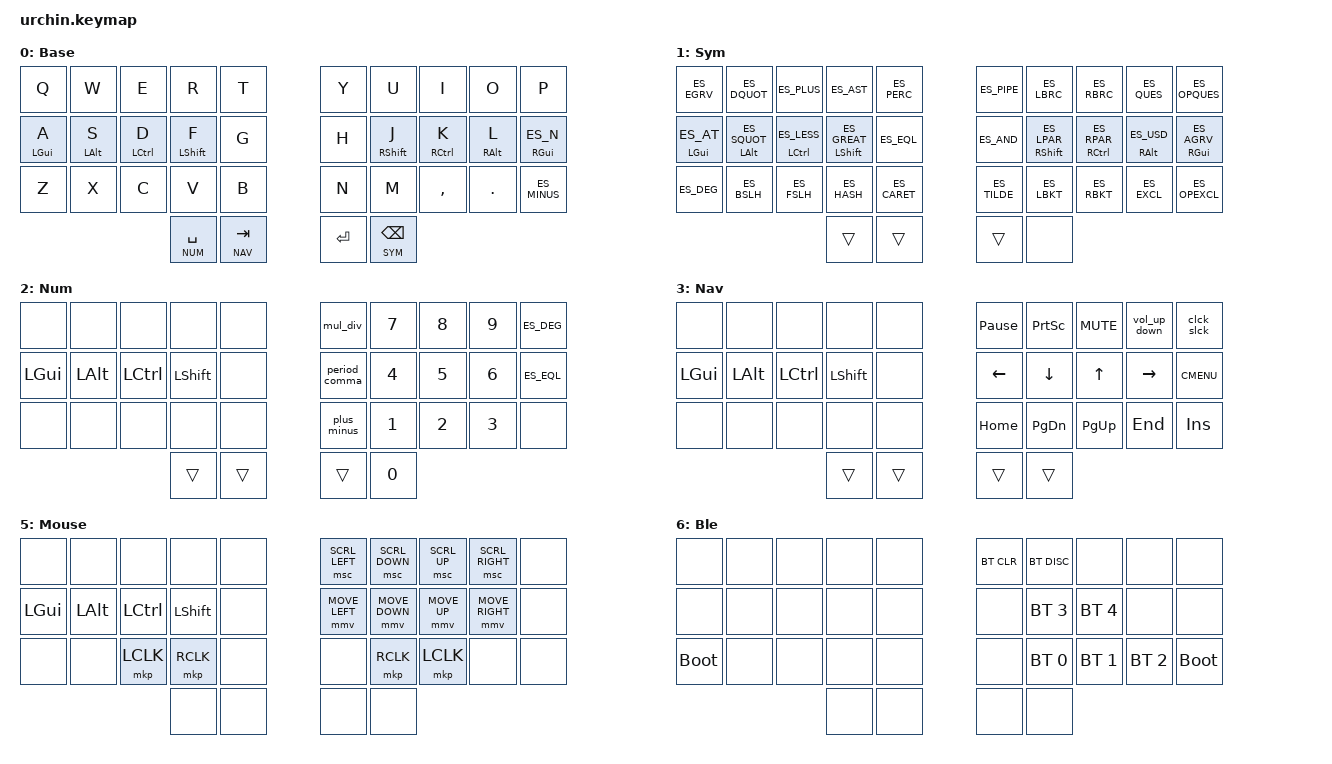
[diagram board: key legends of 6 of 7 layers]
/*
 * Copyright (c) 2020 duckyb
 *
 * SPDX-License-Identifier: MIT`
 */

#include <behaviors.dtsi>
#include <dt-bindings/zmk/keys.h>
#include <dt-bindings/zmk/bt.h>
#include <dt-bindings/zmk/outputs.h>

#define ZMK_POINTING_DEFAULT_MOVE_VAL 1500  // default: 600
#define ZMK_POINTING_DEFAULT_SCRL_VAL 20    // default: 10
#include <dt-bindings/zmk/pointing.h>

#include "keymap_spanish.h"

// Layer definitions
#define BASE 0
#define SYM 1
#define NUM 2
#define NAV 3
#define FUNC 4
#define MOUSE 5
#define BLE 6
// -----------------

#define xxx &none
#define ___ &trans


// tapping term definition
#define TAP_TERM_MS 300
#define QUICK_TAP_MS 300

// 34 keys physical layout
#define LEFT_KEYS 0 1 2 3 4 10 11 12 13 14 20 21 22 23 24 // left-hand keys
#define RIGHT_KEYS 5 6 7 8 9 15 16 17 18 19 25 26 27 28 29 // right-hand keys
#define THUMBS 30 31 32 33 // thumb keys


&sk {
	// don't release mods on other mods presses
	ignore-modifiers;
};

// layer tap config
&lt {
    flavor = "hold-preferred";
    tapping-term-ms = <TAP_TERM_MS>;
    quick-tap-ms = <QUICK_TAP_MS>;      // double-tap + hold repeats tap-key
};


/ {
	behaviors {
		// Enables holding the first mod-tap key
		// by performing a tap-release-hold sequence.
		// To use it: "&qt KEYCODE1 KEYCODE2"
		qt: quick_tap {
			compatible = "zmk,behavior-hold-tap";
			//label = "QUICK_TAP";
			#binding-cells = <2>;
			flavor = "hold-preferred";
			tapping-term-ms = <200>;
			quick-tap-ms = <200>;
			bindings = <&kp>, <&kp>;
		};

		// HOME ROW MODS
		hml: left_hand_positional_hold_tap {
			compatible = "zmk,behavior-hold-tap";
			#binding-cells = <2>;
			flavor = "balanced";
			tapping-term-ms = <TAP_TERM_MS>;
			quick-tap-ms = <QUICK_TAP_MS>;       // double-tap + hold repeats tap-key
			require-prior-idle-ms = <150>;       // do not activate HOLD during typing flow
			bindings = <&kp>, <&kp>;
			hold-trigger-key-positions = <RIGHT_KEYS THUMBS>;
			hold-trigger-on-release;
		};

		hmr: right_hand_positional_hold_tap {
			compatible = "zmk,behavior-hold-tap";
			#binding-cells = <2>;
			flavor = "balanced";
			tapping-term-ms = <TAP_TERM_MS>;
			quick-tap-ms = <QUICK_TAP_MS>;       // double-tap + hold repeats tap-key
			require-prior-idle-ms = <150>;       // do not activate HOLD during typing flow
			bindings = <&kp>, <&kp>;
			hold-trigger-key-positions = <LEFT_KEYS THUMBS>;
			hold-trigger-on-release;
		};

		// TAP DANCES
		plus_minus: plus_minus {
			compatible = "zmk,behavior-mod-morph";
			#binding-cells = <0>;
			bindings = <&kp ES_PLUS>, <&kp KP_MINUS>;
			mods = <(MOD_LSFT)>;
		};

		mul_div: mul_div {
			compatible = "zmk,behavior-mod-morph";
			#binding-cells = <0>;
			bindings = <&kp ES_AST>, <&kp ES_FSLH>;
			mods = <(MOD_LSFT)>;
		};

		period_comma: period_comma {
			compatible = "zmk,behavior-mod-morph";
			#binding-cells = <0>;
			bindings = <&kp PERIOD>, <&kp COMMA>;
			mods = <(MOD_LSFT)>;
		};

		clck_slck: clck_slck {
			compatible = "zmk,behavior-mod-morph";
			#binding-cells = <0>;
			bindings = <&kp CAPS>, <&kp SLCK>;
			mods = <(MOD_LSFT)>;
		};

		vol_up_down: vol_up_down {
			compatible = "zmk,behavior-mod-morph";
			#binding-cells = <0>;
			bindings = <&kp C_VOL_UP>, <&kp C_VOL_DN>;
			mods = <(MOD_LSFT)>;
		};
	};

	macros {
		// sometimes my device thinks a modifier is being held down
		// pressing all modifiers fixes it.
		unstick: unstick {
			//label = "ZM_unstick";
			compatible = "zmk,behavior-macro";
			#binding-cells = <0>;
			bindings = <&kp LSHIFT &kp RSHIFT &kp LCTRL &kp RCTRL &kp LALT &kp RALT &kp LGUI &kp RGUI>;
		};
	};

	combos {
		compatible = "zmk,combos";
		// both left thumb keys
		combo_function_keys {
			timeout-ms = <200>;
			key-positions = <30 31>;
			bindings = <&mo FUNC>;
		};

		combo_ble {
			timeout-ms = <200>;
			key-positions = <31 32>;
			bindings = <&mo BLE>;
		};

		combo_mouse {
			timeout-ms = <200>;
			key-positions = <31 33>;
			bindings = <&to MOUSE>;
		};

		combo_back_to_base {
			timeout-ms = <200>;
			key-positions = <23 24>;
			bindings = <&to BASE>;
			layers = <MOUSE>;
		};
		// left index & middle fingers (home-row)
		// hold control & space for Adobe workflow
		//combo_ctrl_space {
		//	timeout-ms = <200>;
		//	key-positions = <12 13>;
		//	bindings = <&kp LC(SPACE)>;
		//	layers = <BASE>;
		//};

    combo_esc {
        timeout-ms = <30>;
        key-positions = <22 23>; // keys that trigger it
        bindings = <&kp ESC>;
    };

    combo_supr {
        timeout-ms = <30>;
        key-positions = <26 27>; // keys that trigger it
        bindings = <&kp DEL>;
    };

	};

	keymap {
		compatible = "zmk,keymap";
		// Base alpha layer
		default_layer {
			label = "Base";
			bindings = <
				//╭──────────────┬──────────────┬──────────────┬──────────────┬──────────────╮   ╭──────────────┬──────────────┬──────────────┬──────────────┬──────────────╮
						&kp Q          &kp W          &kp E          &kp R          &kp T               &kp Y         &kp U          &kp I          &kp O          &kp P
				//├──────────────┼──────────────┼──────────────┼──────────────┼──────────────┤   ├──────────────┼──────────────┼──────────────┼──────────────┼──────────────┤
						&hml LGUI A    &hml LALT S    &hml LCTRL  D  &hml LSHFT F   &kp G               &kp H         &hmr RSHFT J  &hmr RCTRL K   &hmr RALT L    &hmr RGUI ES_N
				//├──────────────┼──────────────┼──────────────┼──────────────┼──────────────┤   ├──────────────┼──────────────┼──────────────┼──────────────┼──────────────┤
						&kp Z          &kp X          &kp C          &kp V          &kp B               &kp N         &kp M          &kp COMMA      &kp PERIOD     &kp ES_MINUS
				//╰──────────────┴──────────────┼──────────────┼──────────────┼──────────────┤   ├──────────────┼──────────────┼──────────────┼──────────────┴──────────────╯
																												 &lt NUM SPACE  &lt NAV TAB  				&kp RET 		  &lt SYM BSPC
             //                              					 ╰──────────────┴──────────────╯   ╰──────────────┴──────────────╯	
			>;
		};

		// High frequency symbols
		sym_layer {
			label = "Sym";
			bindings = <
				//╭──────────────┬──────────────┬──────────────┬──────────────┬──────────────╮     ╭──────────────┬──────────────┬──────────────┬──────────────┬──────────────╮
					  &kp ES_EGRV    &kp ES_DQUOT   &kp ES_PLUS    &kp ES_AST      &kp ES_PERC          &kp ES_PIPE   &kp ES_LBRC    &kp ES_RBRC    &kp ES_QUES    &kp ES_OPQUES
				//├──────────────┼──────────────┼──────────────┼──────────────┼──────────────┤     ├──────────────┼──────────────┼──────────────┼──────────────┼──────────────┤
			&hml LGUI ES_AT &hml LALT ES_SQUOT &hml LCTRL ES_LESS &hml LSHFT ES_GREAT &kp ES_EQL &kp ES_AND &hmr RSHFT ES_LPAR &hmr RCTRL ES_RPAR &hmr RALT ES_USD &hmr RGUI ES_AGRV
				//├──────────────┼──────────────┼──────────────┼──────────────┼──────────────┤     ├──────────────┼──────────────┼──────────────┼──────────────┼──────────────┤
					  &kp ES_DEG     &kp ES_BSLH    &kp ES_FSLH    &kp ES_HASH     &kp ES_CARET        &kp ES_TILDE  &kp ES_LBKT    &kp ES_RBKT    &kp ES_EXCL    &kp ES_OPEXCL
				//╰──────────────┴──────────────┼──────────────┼──────────────┼──────────────┤     ├──────────────┼──────────────┼──────────────┼──────────────┴──────────────╯
																													  ___            ___                  ___            xxx          
             //                                        ╰──────────────┴──────────────╯     ╰──────────────┴──────────────╯
			>;
		};

		// Number and math layer
		num_layer {
			label = "Num";
			bindings = <
				//╭──────────────┬──────────────┬──────────────┬──────────────┬──────────────╮     ╭──────────────┬──────────────┬──────────────┬──────────────┬──────────────╮
					  xxx            xxx            xxx            xxx            xxx                  &mul_div       &kp N7         &kp N8         &kp N9         &kp ES_DEG
				//├──────────────┼──────────────┼──────────────┼──────────────┼──────────────┤     ├──────────────┼──────────────┼──────────────┼──────────────┼──────────────┤
						&kp LGUI       &kp LALT       &kp LCTRL      &kp LSHFT      xxx                  &period_comma  &kp N4         &kp N5         &kp N6         &kp ES_EQL
				//├──────────────┼──────────────┼──────────────┼──────────────┼──────────────┤     ├──────────────┼──────────────┼──────────────┼──────────────┼──────────────┤
					  xxx            xxx            xxx            xxx            xxx                  &plus_minus    &kp N1         &kp N2         &kp N3         xxx
				//╰──────────────┴──────────────┼──────────────┼──────────────┼──────────────┤     ├──────────────┼──────────────┼──────────────┼──────────────┴──────────────╯
																													  ___            ___                  ___         &kp N0          
             //                                        ╰──────────────┴──────────────╯     ╰──────────────┴──────────────╯
			>;
		};

		// Navigation
		nav_layer {
			label = "Nav";
			bindings = <
				//╭──────────────┬──────────────┬──────────────┬──────────────┬──────────────╮     ╭──────────────┬──────────────┬──────────────┬──────────────┬──────────────╮
					  xxx            xxx            xxx            xxx            xxx                &kp PAUSE_BREAK  &kp PSCRN  		 &kp C_MUTE     &vol_up_down   &clck_slck
				//├──────────────┼──────────────┼──────────────┼──────────────┼──────────────┤     ├──────────────┼──────────────┼──────────────┼──────────────┼──────────────┤
						&kp LGUI       &kp LALT       &kp LCTRL      &kp LSHFT      xxx                  &kp LEFT       &kp DOWN       &kp UP         &kp RIGHT      &kp K_CMENU
				//├──────────────┼──────────────┼──────────────┼──────────────┼──────────────┤     ├──────────────┼──────────────┼──────────────┼──────────────┼──────────────┤
					  xxx            xxx            xxx            xxx            xxx                  &kp HOME       &kp PG_DN      &kp PG_UP      &kp END        &kp INS
				//╰──────────────┴──────────────┼──────────────┼──────────────┼──────────────┤     ├──────────────┼──────────────┼──────────────┼──────────────┴──────────────╯
																													  ___            ___                  ___            ___
             //                                        ╰──────────────┴──────────────╯     ╰──────────────┴──────────────╯
			>;
		};

		//Function
		func_layer {
			label = "Func";
			bindings = <
				//╭──────────────┬──────────────┬──────────────┬──────────────┬──────────────╮     ╭──────────────┬──────────────┬──────────────┬──────────────┬──────────────╮
					  xxx            xxx            xxx            xxx            xxx                  &kp F12        &kp F7         &kp F8         &kp F9         xxx
				//├──────────────┼──────────────┼──────────────┼──────────────┼──────────────┤     ├──────────────┼──────────────┼──────────────┼──────────────┼──────────────┤
						&kp LGUI       &kp LALT       &kp LCTRL      &kp LSHFT      xxx                  &kp F11        &kp F4         &kp F5         &kp F6         xxx
				//├──────────────┼──────────────┼──────────────┼──────────────┼──────────────┤     ├──────────────┼──────────────┼──────────────┼──────────────┼──────────────┤
					  xxx            xxx            xxx            xxx            xxx                                 &kp F1         &kp F2         &kp F3         xxx
				//╰──────────────┴──────────────┼──────────────┼──────────────┼──────────────┤     ├──────────────┼──────────────┼──────────────┼──────────────┴──────────────╯
																													  ___            ___                  ___         &kp F10          
             //                                        ╰──────────────┴──────────────╯     ╰──────────────┴──────────────╯
			>;
		};

		// Mouse
		mouse_layer {
			label = "Mouse";
			bindings = <
				//╭──────────────┬──────────────┬──────────────┬──────────────┬──────────────╮     ╭──────────────┬──────────────┬──────────────┬──────────────┬──────────────╮
					  xxx            xxx            xxx            xxx            xxx                  &msc SCRL_LEFT &msc SCRL_DOWN &msc SCRL_UP  &msc SCRL_RIGHT xxx
				//├──────────────┼──────────────┼──────────────┼──────────────┼──────────────┤     ├──────────────┼──────────────┼──────────────┼──────────────┼──────────────┤
						&kp LGUI       &kp LALT       &kp LCTRL      &kp LSHFT      xxx                  &mmv MOVE_LEFT &mmv MOVE_DOWN &mmv MOVE_UP  &mmv MOVE_RIGHT xxx
				//├──────────────┼──────────────┼──────────────┼──────────────┼──────────────┤     ├──────────────┼──────────────┼──────────────┼──────────────┼──────────────┤
					  xxx            xxx            &mkp LCLK      &mkp RCLK      xxx                  xxx            &mkp RCLK      &mkp LCLK     xxx             xxx
				//╰──────────────┴──────────────┼──────────────┼──────────────┼──────────────┤     ├──────────────┼──────────────┼──────────────┼──────────────┴──────────────╯
																													  xxx         xxx                  xxx            xxx 
             //                                        ╰──────────────┴──────────────╯     ╰──────────────┴──────────────╯
			>;
		};

		// Bluetooth
		ble_layer {
			label = "Ble";
			bindings = <
				//╭──────────────┬──────────────┬──────────────┬──────────────┬──────────────╮     ╭──────────────┬──────────────┬──────────────┬──────────────┬──────────────╮
					  xxx            xxx            xxx            xxx            xxx                  &bt BT_CLR     &bt BT_DISC    xxx		        xxx            xxx	
				//├──────────────┼──────────────┼──────────────┼──────────────┼──────────────┤     ├──────────────┼──────────────┼──────────────┼──────────────┼──────────────┤
						xxx            xxx            xxx            xxx            xxx                  xxx            &bt BT_SEL 3   &bt BT_SEL 4   xxx            xxx
				//├──────────────┼──────────────┼──────────────┼──────────────┼──────────────┤     ├──────────────┼──────────────┼──────────────┼──────────────┼──────────────┤
					  &bootloader    xxx            xxx            xxx            xxx                  xxx            &bt BT_SEL 0   &bt BT_SEL 1   &bt BT_SEL 2   &bootloader
				//╰──────────────┴──────────────┼──────────────┼──────────────┼──────────────┤     ├──────────────┼──────────────┼──────────────┼──────────────┴──────────────╯
																													  xxx            xxx               xxx            xxx 
             //                                        ╰──────────────┴──────────────╯     ╰──────────────┴──────────────╯
			>;
		};
	};
};

//		// Main modifiers and arrow keys
//		ext_layer {
//			//label = "Mods";
//			bindings = <
//			&kp ESC  &kp C_PREV &kp C_PP  &kp C_NEXT  &kp C_PAUSE    	&kp PG_UP  &kp HOME &kp UP &kp END &kp CAPS
//			&sk LALT &sk LGUI  &sk LSHIFT  &sk LCTRL  &kp RALT 			&kp PG_DN &kp LEFT  &kp DOWN  &kp RIGHT   &kp DEL
//			&kp LC(Z)  &kp LC(X) &kp LC(C) &kp TAB   &kp LC(V)          &kp LC(BSPC) &kp BSPC &trans &trans  &trans
//																		&trans &kp LCTRL    &kp ENTER  &mo FNC 
//			>;
//		};
//
//		// Used to change the keyboard's settings.
//		settings_layer {
//				//label = "Sett.";
//				bindings = <
//				&bootloader &none &none &bt BT_CLR &bt BT_SEL 0               &bt BT_SEL 3 &none &unstick &none &bootloader 
//				&none &none &none &none      &bt BT_SEL 1 						  &bt BT_SEL 4 &none &none &none &none
//				&studio_unlock &none &none &none      &bt BT_SEL 2               &bt BT_SEL 5 &none &none &none &studio_unlock
//										&none &none                         &none &none 
//				>;
//		};
//	};
//};
//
